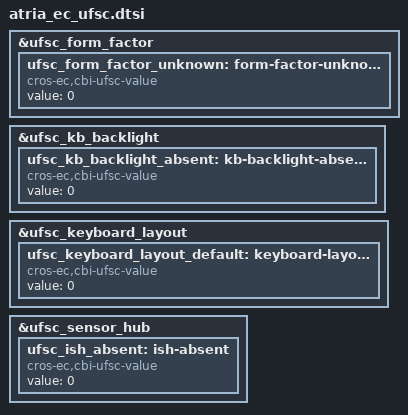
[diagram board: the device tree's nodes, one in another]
/* Copyright 2026 The ChromiumOS Authors
 * Use of this source code is governed by a BSD-style license that can be
 * found in the LICENSE file.
 */

#include <cros/cbi_ufsc_std_schema.dtsi>

/* Auto-generated by generate_ufsc.py */

&ufsc_form_factor {
	ufsc_form_factor_unknown: form-factor-unknown {
		compatible = "cros-ec,cbi-ufsc-value";
		status = "okay";
		value = <0>;
	};
};

&ufsc_kb_backlight {
	ufsc_kb_backlight_absent: kb-backlight-absent {
		compatible = "cros-ec,cbi-ufsc-value";
		status = "okay";
		value = <0>;
	};
};

&ufsc_keyboard_layout {
	ufsc_keyboard_layout_default: keyboard-layout-default {
		compatible = "cros-ec,cbi-ufsc-value";
		status = "okay";
		value = <0>;
	};
};

&ufsc_sensor_hub {
	ufsc_ish_absent: ish-absent {
		compatible = "cros-ec,cbi-ufsc-value";
		status = "okay";
		value = <0>;
	};
};

